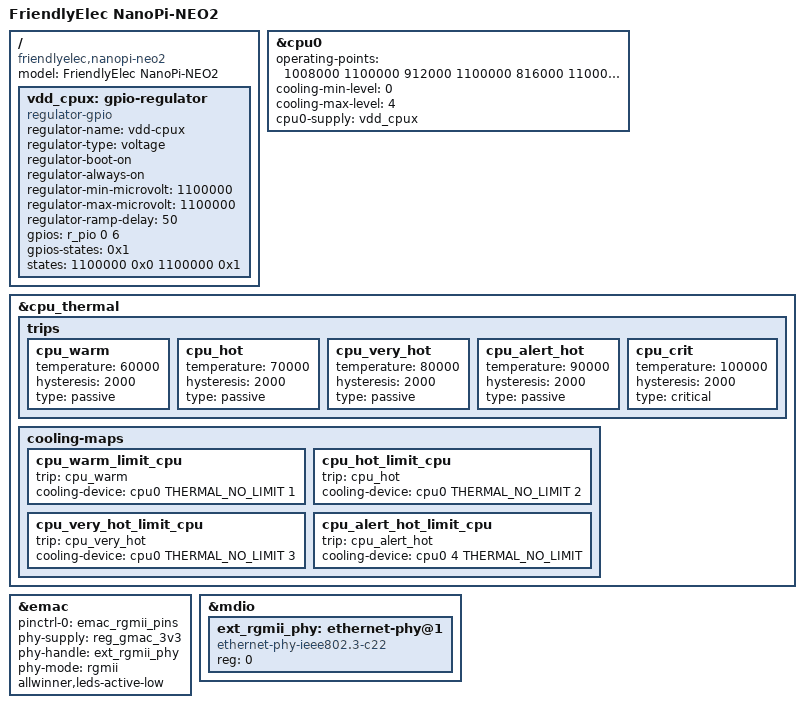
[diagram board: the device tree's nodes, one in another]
/*
 * Copyright (C) 2016 ARM Ltd.
 *
 * This file is dual-licensed: you can use it either under the terms
 * of the GPL or the X11 license, at your option. Note that this dual
 * licensing only applies to this file, and not this project as a
 * whole.
 *
 *  a) This file is free software; you can redistribute it and/or
 *     modify it under the terms of the GNU General Public License as
 *     published by the Free Software Foundation; either version 2 of the
 *     License, or (at your option) any later version.
 *
 *     This file is distributed in the hope that it will be useful,
 *     but WITHOUT ANY WARRANTY; without even the implied warranty of
 *     MERCHANTABILITY or FITNESS FOR A PARTICULAR PURPOSE.  See the
 *     GNU General Public License for more details.
 *
 * Or, alternatively,
 *
 *  b) Permission is hereby granted, free of charge, to any person
 *     obtaining a copy of this software and associated documentation
 *     files (the "Software"), to deal in the Software without
 *     restriction, including without limitation the rights to use,
 *     copy, modify, merge, publish, distribute, sublicense, and/or
 *     sell copies of the Software, and to permit persons to whom the
 *     Software is furnished to do so, subject to the following
 *     conditions:
 *
 *     The above copyright notice and this permission notice shall be
 *     included in all copies or substantial portions of the Software.
 *
 *     THE SOFTWARE IS PROVIDED "AS IS", WITHOUT WARRANTY OF ANY KIND,
 *     EXPRESS OR IMPLIED, INCLUDING BUT NOT LIMITED TO THE WARRANTIES
 *     OF MERCHANTABILITY, FITNESS FOR A PARTICULAR PURPOSE AND
 *     NONINFRINGEMENT. IN NO EVENT SHALL THE AUTHORS OR COPYRIGHT
 *     HOLDERS BE LIABLE FOR ANY CLAIM, DAMAGES OR OTHER LIABILITY,
 *     WHETHER IN AN ACTION OF CONTRACT, TORT OR OTHERWISE, ARISING
 *     FROM, OUT OF OR IN CONNECTION WITH THE SOFTWARE OR THE USE OR
 *     OTHER DEALINGS IN THE SOFTWARE.
 */

#include "sun50i-h5-nanopi.dtsi"

/ {
	model = "FriendlyElec NanoPi-NEO2";
	compatible = "friendlyelec,nanopi-neo2", "allwinner,sun50i-h5";

	vdd_cpux: gpio-regulator {
		compatible = "regulator-gpio";

		regulator-name = "vdd-cpux";
		regulator-type = "voltage";
		regulator-boot-on;
		regulator-always-on;
		regulator-min-microvolt = <1100000>;
		regulator-max-microvolt = <1100000>;
		regulator-ramp-delay = <50>; /* 4ms */

		gpios = <&r_pio 0 6 GPIO_ACTIVE_HIGH>;
		gpios-states = <0x1>;
		states = <1100000 0x0
			  1100000 0x1>;
	};
};

&cpu0 {
	operating-points = <
		1008000	1100000
		912000	1100000
		816000	1100000
		624000	1100000
		480000	1100000
		>;
	#cooling-cells = <2>;
	cooling-min-level = <0>;
	cooling-max-level = <4>;
	cpu0-supply = <&vdd_cpux>;
};

&cpu_thermal {
	trips {
		cpu_warm: cpu_warm {
			temperature = <60000>;
			hysteresis = <2000>;
			type = "passive";
		};
		cpu_hot: cpu_hot {
			temperature = <70000>;
			hysteresis = <2000>;
			type = "passive";
		};
		cpu_very_hot: cpu_very_hot {
			temperature = <80000>;
			hysteresis = <2000>;
			type = "passive";
		};
		cpu_alert_hot: cpu_alert_hot {
			temperature = <90000>;
			hysteresis = <2000>;
			type = "passive";
		};
		cpu_crit: cpu_crit {
			temperature = <100000>;
			hysteresis = <2000>;
			type = "critical";
		};
	};

	cooling-maps {
		cpu_warm_limit_cpu {
			trip = <&cpu_warm>;
			cooling-device = <&cpu0 THERMAL_NO_LIMIT 1>;
		};
		cpu_hot_limit_cpu {
			trip = <&cpu_hot>;
			cooling-device = <&cpu0 THERMAL_NO_LIMIT 2>;
		};
		cpu_very_hot_limit_cpu {
			trip = <&cpu_very_hot>;
			cooling-device = <&cpu0 THERMAL_NO_LIMIT 3>;
		};
		cpu_alert_hot_limit_cpu {
			trip = <&cpu_alert_hot>;
			cooling-device = <&cpu0 4 THERMAL_NO_LIMIT>;
		};
	};
};

&emac {
	pinctrl-names = "default";
	pinctrl-0 = <&emac_rgmii_pins>;
	phy-supply = <&reg_gmac_3v3>;
	phy-handle = <&ext_rgmii_phy>;
	phy-mode = "rgmii";
	allwinner,leds-active-low;
	status = "okay";
};

&mdio {
	ext_rgmii_phy: ethernet-phy@1 {
		compatible = "ethernet-phy-ieee802.3-c22";
		reg = <0>;
	};
};
